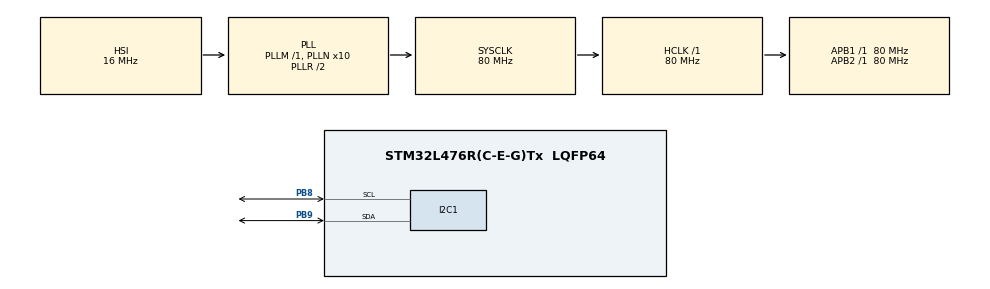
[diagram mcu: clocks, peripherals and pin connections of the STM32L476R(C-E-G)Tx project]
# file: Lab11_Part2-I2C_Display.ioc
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I2C1.Timing=0x10D19CE4
Mcu.Family=STM32L4
Mcu.Name=STM32L476R(C-E-G)Tx
Mcu.Package=LQFP64
NVIC.PriorityGroup=NVIC_PRIORITYGROUP_4
PA13\ (JTMS-SWDIO).GPIO_Label=TMS
PA13\ (JTMS-SWDIO).Mode=Serial_Wire
PA13\ (JTMS-SWDIO).Signal=SYS_JTMS-SWDIO
PA14\ (JTCK-SWCLK).GPIO_Label=TCK
PA14\ (JTCK-SWCLK).Mode=Serial_Wire
PA14\ (JTCK-SWCLK).Signal=SYS_JTCK-SWCLK
PB3\ (JTDO-TRACESWO).GPIO_Label=SWO
PB3\ (JTDO-TRACESWO).Signal=SYS_JTDO-SWO
PB8.Mode=I2C
PB8.Signal=I2C1_SCL
PB9.Mode=I2C
PB9.Signal=I2C1_SDA
PC14-OSC32_IN\ (PC14).Mode=LSE-External-Oscillator
PC14-OSC32_IN\ (PC14).Signal=RCC_OSC32_IN
PC15-OSC32_OUT\ (PC15).Mode=LSE-External-Oscillator
PC15-OSC32_OUT\ (PC15).Signal=RCC_OSC32_OUT
PH0-OSC_IN\ (PH0).Signal=RCC_OSC_IN
PH1-OSC_OUT\ (PH1).Signal=RCC_OSC_OUT
ProjectManager.HeapSize=0x200
ProjectManager.StackSize=0x400
ProjectManager.TargetToolchain=STM32CubeIDE
RCC.ADCFreq_Value=64000000
RCC.AHBFreq_Value=80000000
RCC.APB1Freq_Value=80000000
RCC.APB1TimFreq_Value=80000000
RCC.APB2Freq_Value=80000000
RCC.APB2TimFreq_Value=80000000
RCC.CortexFreq_Value=80000000
RCC.HCLKFreq_Value=80000000
RCC.HSE_VALUE=8000000
RCC.HSI_VALUE=16000000
RCC.MSI_VALUE=4000000
RCC.PLLN=10
RCC.PLLSourceVirtual=RCC_PLLSOURCE_HSI
RCC.PREFETCH_ENABLE=1
RCC.SYSCLKFreq_VALUE=80000000
RCC.SYSCLKSource=RCC_SYSCLKSOURCE_PLLCLK
RCC.USBFreq_Value=64000000
RCC.VCOOutputFreq_Value=160000000
board=NUCLEO-L476RG

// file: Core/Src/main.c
/* USER CODE BEGIN Header */
/**
  ******************************************************************************
  * @file           : main.c
  * @brief          : Main program body
  ******************************************************************************
  * @attention
  *
  * Copyright (c) 2025 STMicroelectronics.
  * All rights reserved.
  *
  * This software is licensed under terms that can be found in the LICENSE file
  * in the root directory of this software component.
  * If no LICENSE file comes with this software, it is provided AS-IS.
  *
  ******************************************************************************
  */
/* USER CODE END Header */
#include "main.h"

/* USER CODE BEGIN PM */
#define I2C_ADDR 0x27 // I2C address of the PCF8574
#define RS_BIT 0 // Register select bit
#define EN_BIT 2 // Enable bit
#define BL_BIT 3 // Backlight bit
#define D4_BIT 4 // Data 4 bit
#define D5_BIT 5 // Data 5 bit
#define D6_BIT 6 // Data 6 bit
#define D7_BIT 7 // Data 7 bit
#define LCD_ROWS 2 // Number of rows on the LCD
#define LCD_COLS 16 // Number of columns on the LCD
/* USER CODE END PM */

I2C_HandleTypeDef hi2c1;

/* USER CODE BEGIN PV */
uint8_t backlight_state = 1;
/* USER CODE END PV */

void SystemClock_Config(void);
static void MX_GPIO_Init(void);
static void MX_I2C1_Init(void);

/* USER CODE BEGIN 0 */
void lcd_write_nibble(uint8_t nibble, uint8_t rs) {
	 uint8_t data = nibble << D4_BIT;
	 data |= rs << RS_BIT;
	 data |= backlight_state << BL_BIT; // Include backlight state in data
	 data |= 1 << EN_BIT;
	 HAL_I2C_Master_Transmit(&hi2c1, I2C_ADDR << 1, &data, 1, 100);
	 HAL_Delay(1);
	 data &= ~(1 << EN_BIT);
	 HAL_I2C_Master_Transmit(&hi2c1, I2C_ADDR << 1, &data, 1, 100);
}

void lcd_send_cmd(uint8_t cmd) {
	 uint8_t upper_nibble = cmd >> 4;
	 uint8_t lower_nibble = cmd & 0x0F;
	 lcd_write_nibble(upper_nibble, 0);
	 lcd_write_nibble(lower_nibble, 0);
	 if (cmd == 0x01 || cmd == 0x02) {
		 HAL_Delay(2);
	 }
}

void lcd_send_data(uint8_t data) {
	 uint8_t upper_nibble = data >> 4;
	 uint8_t lower_nibble = data & 0x0F;
	 lcd_write_nibble(upper_nibble, 1);
	 lcd_write_nibble(lower_nibble, 1);
}

void lcd_init() {
	 HAL_Delay(50);
	 lcd_write_nibble(0x03, 0);
	 HAL_Delay(5);
	 lcd_write_nibble(0x03, 0);
	 HAL_Delay(1);
	 lcd_write_nibble(0x03, 0);
	 HAL_Delay(1);
	 lcd_write_nibble(0x02, 0);
	 lcd_send_cmd(0x28);
	 lcd_send_cmd(0x0C);
	 lcd_send_cmd(0x06);
	 lcd_send_cmd(0x01);
	 HAL_Delay(2);
}

void lcd_write_string(char *str) {
	 while (*str) {
		 lcd_send_data(*str++);
	 }
}

void lcd_set_cursor(uint8_t row, uint8_t column) {
	 uint8_t address;
	 switch (row) {
		 case 0:
			 address = 0x00;
			 break;
		 case 1:
			 address = 0x40;
			 break;
		 default:
			 address = 0x00;
	 }
	 address += column;
	 lcd_send_cmd(0x80 | address);
}

void lcd_clear(void) {
	lcd_send_cmd(0x01);
	 HAL_Delay(2);
}

void lcd_backlight(uint8_t state) {
	 if (state) {
		 backlight_state = 1;
	 } else {
		 backlight_state = 0;
	 }
}
/* USER CODE END 0 */

int main(void)
{

  /* MCU Configuration--------------------------------------------------------*/

  /* Reset of all peripherals, Initializes the Flash interface and the Systick. */
  HAL_Init();

  /* Configure the system clock */
  SystemClock_Config();

  /* Initialize all configured peripherals */
  MX_GPIO_Init();
  MX_I2C1_Init();
  /* USER CODE BEGIN 2 */
  // I2C pull-up resistors
  GPIOB->PUPDR |= 0b01 << (8*2);
  GPIOB->PUPDR |= 0b01 << (9*2);
  // Initialize the LCD
  lcd_init();
  lcd_backlight(1); // Turn on backlight
  // Write a string to the LCD
  lcd_write_string("Hello, world!");
  /* USER CODE END 2 */

  /* Infinite loop */
  while (1)
  {

  }
}

void SystemClock_Config(void)
{
  RCC_OscInitTypeDef RCC_OscInitStruct = {0};
  RCC_ClkInitTypeDef RCC_ClkInitStruct = {0};

  /** Configure the main internal regulator output voltage
  */
  if (HAL_PWREx_ControlVoltageScaling(PWR_REGULATOR_VOLTAGE_SCALE1) != HAL_OK)
  {
    Error_Handler();
  }

  /** Initializes the RCC Oscillators according to the specified parameters
  * in the RCC_OscInitTypeDef structure.
  */
  RCC_OscInitStruct.OscillatorType = RCC_OSCILLATORTYPE_HSI;
  RCC_OscInitStruct.HSIState = RCC_HSI_ON;
  RCC_OscInitStruct.HSICalibrationValue = RCC_HSICALIBRATION_DEFAULT;
  RCC_OscInitStruct.PLL.PLLState = RCC_PLL_ON;
  RCC_OscInitStruct.PLL.PLLSource = RCC_PLLSOURCE_HSI;
  RCC_OscInitStruct.PLL.PLLM = 1;
  RCC_OscInitStruct.PLL.PLLN = 10;
  RCC_OscInitStruct.PLL.PLLP = RCC_PLLP_DIV7;
  RCC_OscInitStruct.PLL.PLLQ = RCC_PLLQ_DIV2;
  RCC_OscInitStruct.PLL.PLLR = RCC_PLLR_DIV2;
  if (HAL_RCC_OscConfig(&RCC_OscInitStruct) != HAL_OK)
  {
    Error_Handler();
  }

  /** Initializes the CPU, AHB and APB buses clocks
  */
  RCC_ClkInitStruct.ClockType = RCC_CLOCKTYPE_HCLK|RCC_CLOCKTYPE_SYSCLK
                              |RCC_CLOCKTYPE_PCLK1|RCC_CLOCKTYPE_PCLK2;
  RCC_ClkInitStruct.SYSCLKSource = RCC_SYSCLKSOURCE_PLLCLK;
  RCC_ClkInitStruct.AHBCLKDivider = RCC_SYSCLK_DIV1;
  RCC_ClkInitStruct.APB1CLKDivider = RCC_HCLK_DIV1;
  RCC_ClkInitStruct.APB2CLKDivider = RCC_HCLK_DIV1;

  if (HAL_RCC_ClockConfig(&RCC_ClkInitStruct, FLASH_LATENCY_4) != HAL_OK)
  {
    Error_Handler();
  }
}

static void MX_I2C1_Init(void)
{

  hi2c1.Instance = I2C1;
  hi2c1.Init.Timing = 0x10D19CE4;
  hi2c1.Init.OwnAddress1 = 0;
  hi2c1.Init.AddressingMode = I2C_ADDRESSINGMODE_7BIT;
  hi2c1.Init.DualAddressMode = I2C_DUALADDRESS_DISABLE;
  hi2c1.Init.OwnAddress2 = 0;
  hi2c1.Init.OwnAddress2Masks = I2C_OA2_NOMASK;
  hi2c1.Init.GeneralCallMode = I2C_GENERALCALL_DISABLE;
  hi2c1.Init.NoStretchMode = I2C_NOSTRETCH_DISABLE;
  if (HAL_I2C_Init(&hi2c1) != HAL_OK)
  {
    Error_Handler();
  }

  /** Configure Analogue filter
  */
  if (HAL_I2CEx_ConfigAnalogFilter(&hi2c1, I2C_ANALOGFILTER_ENABLE) != HAL_OK)
  {
    Error_Handler();
  }

  /** Configure Digital filter
  */
  if (HAL_I2CEx_ConfigDigitalFilter(&hi2c1, 0) != HAL_OK)
  {
    Error_Handler();
  }

}

static void MX_GPIO_Init(void)
{

  /* GPIO Ports Clock Enable */
  __HAL_RCC_GPIOC_CLK_ENABLE();
  __HAL_RCC_GPIOH_CLK_ENABLE();
  __HAL_RCC_GPIOA_CLK_ENABLE();
  __HAL_RCC_GPIOB_CLK_ENABLE();

}

void Error_Handler(void)
{
  __disable_irq();
  while (1)
  {
  }
}
